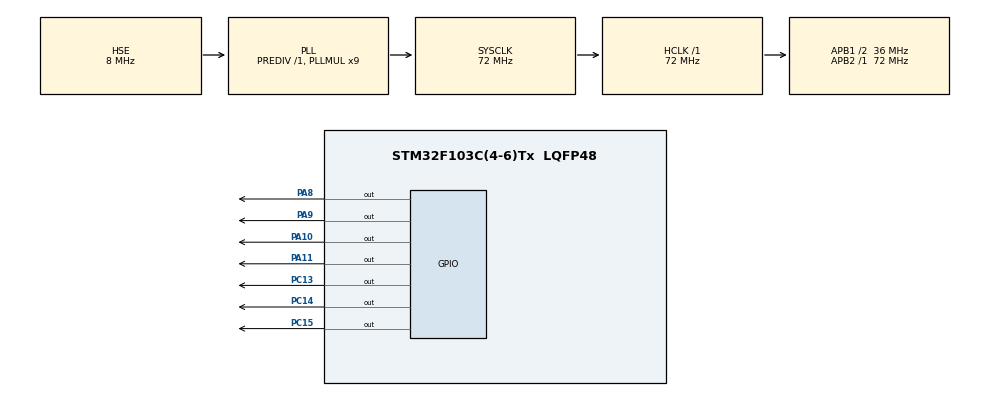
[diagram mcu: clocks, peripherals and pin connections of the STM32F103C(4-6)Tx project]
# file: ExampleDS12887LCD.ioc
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Mcu.Family=STM32F1
Mcu.Name=STM32F103C(4-6)Tx
Mcu.Package=LQFP48
NVIC.PriorityGroup=NVIC_PRIORITYGROUP_4
PA10.GPIO_ModeDefaultOutputPP=GPIO_MODE_OUTPUT_PP
PA10.GPIO_Speed=GPIO_SPEED_FREQ_HIGH
PA10.PinState=GPIO_PIN_RESET
PA10.Signal=GPIO_Output
PA11.GPIO_ModeDefaultOutputPP=GPIO_MODE_OUTPUT_PP
PA11.GPIO_Speed=GPIO_SPEED_FREQ_HIGH
PA11.PinState=GPIO_PIN_RESET
PA11.Signal=GPIO_Output
PA8.GPIO_ModeDefaultOutputPP=GPIO_MODE_OUTPUT_PP
PA8.GPIO_Speed=GPIO_SPEED_FREQ_HIGH
PA8.PinState=GPIO_PIN_RESET
PA8.Signal=GPIO_Output
PA9.GPIO_ModeDefaultOutputPP=GPIO_MODE_OUTPUT_PP
PA9.GPIO_Speed=GPIO_SPEED_FREQ_HIGH
PA9.PinState=GPIO_PIN_RESET
PA9.Signal=GPIO_Output
PC13-TAMPER-RTC.GPIO_ModeDefaultOutputPP=GPIO_MODE_OUTPUT_PP
PC13-TAMPER-RTC.GPIO_Speed=GPIO_SPEED_FREQ_HIGH
PC13-TAMPER-RTC.PinState=GPIO_PIN_RESET
PC13-TAMPER-RTC.Signal=GPIO_Output
PC14-OSC32_IN.GPIO_ModeDefaultOutputPP=GPIO_MODE_OUTPUT_PP
PC14-OSC32_IN.GPIO_Speed=GPIO_SPEED_FREQ_HIGH
PC14-OSC32_IN.PinState=GPIO_PIN_RESET
PC14-OSC32_IN.Signal=GPIO_Output
PC15-OSC32_OUT.GPIO_ModeDefaultOutputPP=GPIO_MODE_OUTPUT_PP
PC15-OSC32_OUT.GPIO_Speed=GPIO_SPEED_FREQ_HIGH
PC15-OSC32_OUT.PinState=GPIO_PIN_RESET
PC15-OSC32_OUT.Signal=GPIO_Output
PD0-OSC_IN.Mode=HSE-External-Oscillator
PD0-OSC_IN.Signal=RCC_OSC_IN
PD1-OSC_OUT.Mode=HSE-External-Oscillator
PD1-OSC_OUT.Signal=RCC_OSC_OUT
ProjectManager.HeapSize=0x200
ProjectManager.StackSize=0x400
ProjectManager.TargetToolchain=MDK-ARM V5
RCC.AHBFreq_Value=72000000
RCC.APB1CLKDivider=RCC_HCLK_DIV2
RCC.APB1Freq_Value=36000000
RCC.APB1TimFreq_Value=72000000
RCC.APB2Freq_Value=72000000
RCC.APB2TimFreq_Value=72000000
RCC.HCLKFreq_Value=72000000
RCC.PLLMUL=RCC_PLL_MUL9
RCC.PLLSourceVirtual=RCC_PLLSOURCE_HSE
RCC.SYSCLKFreq_VALUE=72000000
RCC.SYSCLKSource=RCC_SYSCLKSOURCE_PLLCLK
RCC.USBFreq_Value=72000000
VP_SYS_VS_ND.Mode=No_Debug
board=ExampleDS12887LCD

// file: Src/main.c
/**
  ******************************************************************************
  * @file           : main.c
  * @brief          : Main program body
  ******************************************************************************
  ** This notice applies to any and all portions of this file
  * that are not between comment pairs USER CODE BEGIN and
  * USER CODE END. Other portions of this file, whether
  * inserted by the user or by software development tools
  * are owned by their respective copyright owners.
  *
  * COPYRIGHT(c) 2018 STMicroelectronics
  *
  * Redistribution and use in source and binary forms, with or without modification,
  * are permitted provided that the following conditions are met:
  *   1. Redistributions of source code must retain the above copyright notice,
  *      this list of conditions and the following disclaimer.
  *   2. Redistributions in binary form must reproduce the above copyright notice,
  *      this list of conditions and the following disclaimer in the documentation
  *      and/or other materials provided with the distribution.
  *   3. Neither the name of STMicroelectronics nor the names of its contributors
  *      may be used to endorse or promote products derived from this software
  *      without specific prior written permission.
  *
  * THIS SOFTWARE IS PROVIDED BY THE COPYRIGHT HOLDERS AND CONTRIBUTORS "AS IS"
  * AND ANY EXPRESS OR IMPLIED WARRANTIES, INCLUDING, BUT NOT LIMITED TO, THE
  * IMPLIED WARRANTIES OF MERCHANTABILITY AND FITNESS FOR A PARTICULAR PURPOSE ARE
  * DISCLAIMED. IN NO EVENT SHALL THE COPYRIGHT HOLDER OR CONTRIBUTORS BE LIABLE
  * FOR ANY DIRECT, INDIRECT, INCIDENTAL, SPECIAL, EXEMPLARY, OR CONSEQUENTIAL
  * DAMAGES (INCLUDING, BUT NOT LIMITED TO, PROCUREMENT OF SUBSTITUTE GOODS OR
  * SERVICES; LOSS OF USE, DATA, OR PROFITS; OR BUSINESS INTERRUPTION) HOWEVER
  * CAUSED AND ON ANY THEORY OF LIABILITY, WHETHER IN CONTRACT, STRICT LIABILITY,
  * OR TORT (INCLUDING NEGLIGENCE OR OTHERWISE) ARISING IN ANY WAY OUT OF THE USE
  * OF THIS SOFTWARE, EVEN IF ADVISED OF THE POSSIBILITY OF SUCH DAMAGE.
  *
  ******************************************************************************
  */
#include "main.h"
#include "stm32f1xx_hal.h"
#include "lcd_txt.h"
#include "DS12887.h"

/* USER CODE BEGIN PV */
/* Private variables ---------------------------------------------------------*/
uint8_t second=0 ,minute=0,hour=16 ,day=1,date=1,month=1,year=20;
char str[32];

/* USER CODE END PV */

void SystemClock_Config(void);
static void MX_GPIO_Init(void);

/* USER CODE BEGIN PFP */
/* Private function prototypes -----------------------------------------------*/

/* USER CODE END PFP */

int main(void)
{

  /* MCU Configuration----------------------------------------------------------*/

  /* Reset of all peripherals, Initializes the Flash interface and the Systick. */
  HAL_Init();

  /* Configure the system clock */
  SystemClock_Config();

  /* Initialize all configured peripherals */
  MX_GPIO_Init();
	lcd_init();
	configpin_GPIO();
	DS12C887_Init();
	DS12C887_SetTime(hour,minute,second);
  DS12C887_SetDate(day,date,month,year);
//lcd_puts(0,0, (int8_t*) "hoang de nho");
  /* Infinite loop */
  /* USER CODE BEGIN WHILE */
  while (1)
  {
		DS12C887_GetTime(&hour,&minute,&second);
		DS12C887_GetDate(&day,&date,&month,&year);
		sprintf(str,"TIME: %2u:%2u:%2u",(uint16_t)hour,(uint16_t)minute,(uint16_t)second);
		lcd_puts(0, 0, str);
		sprintf(str,"DATE :%2u:%2u:%2u",(uint16_t)date,(uint16_t)month,(uint16_t)year);
		lcd_puts(1, 0, str);
		HAL_Delay(100);

  /* USER CODE END WHILE */

  }

}

void SystemClock_Config(void)
{

  RCC_OscInitTypeDef RCC_OscInitStruct;
  RCC_ClkInitTypeDef RCC_ClkInitStruct;

    /**Initializes the CPU, AHB and APB busses clocks
    */
  RCC_OscInitStruct.OscillatorType = RCC_OSCILLATORTYPE_HSE;
  RCC_OscInitStruct.HSEState = RCC_HSE_ON;
  RCC_OscInitStruct.HSEPredivValue = RCC_HSE_PREDIV_DIV1;
  RCC_OscInitStruct.HSIState = RCC_HSI_ON;
  RCC_OscInitStruct.PLL.PLLState = RCC_PLL_ON;
  RCC_OscInitStruct.PLL.PLLSource = RCC_PLLSOURCE_HSE;
  RCC_OscInitStruct.PLL.PLLMUL = RCC_PLL_MUL9;
  if (HAL_RCC_OscConfig(&RCC_OscInitStruct) != HAL_OK)
  {
    _Error_Handler(__FILE__, __LINE__);
  }

    /**Initializes the CPU, AHB and APB busses clocks
    */
  RCC_ClkInitStruct.ClockType = RCC_CLOCKTYPE_HCLK|RCC_CLOCKTYPE_SYSCLK
                              |RCC_CLOCKTYPE_PCLK1|RCC_CLOCKTYPE_PCLK2;
  RCC_ClkInitStruct.SYSCLKSource = RCC_SYSCLKSOURCE_PLLCLK;
  RCC_ClkInitStruct.AHBCLKDivider = RCC_SYSCLK_DIV1;
  RCC_ClkInitStruct.APB1CLKDivider = RCC_HCLK_DIV2;
  RCC_ClkInitStruct.APB2CLKDivider = RCC_HCLK_DIV1;

  if (HAL_RCC_ClockConfig(&RCC_ClkInitStruct, FLASH_LATENCY_2) != HAL_OK)
  {
    _Error_Handler(__FILE__, __LINE__);
  }

    /**Configure the Systick interrupt time
    */
  HAL_SYSTICK_Config(HAL_RCC_GetHCLKFreq()/1000);

    /**Configure the Systick
    */
  HAL_SYSTICK_CLKSourceConfig(SYSTICK_CLKSOURCE_HCLK);

  /* SysTick_IRQn interrupt configuration */
  HAL_NVIC_SetPriority(SysTick_IRQn, 0, 0);
}

/** Configure pins as
        * Analog
        * Input
        * Output
        * EVENT_OUT
        * EXTI
*/
static void MX_GPIO_Init(void)
{

  GPIO_InitTypeDef GPIO_InitStruct;

  /* GPIO Ports Clock Enable */
  __HAL_RCC_GPIOC_CLK_ENABLE();
  __HAL_RCC_GPIOD_CLK_ENABLE();
	 //__HAL_RCC_GPIOB_CLK_ENABLE();
  __HAL_RCC_GPIOA_CLK_ENABLE();

  /*Configure GPIO pin Output Level */
  HAL_GPIO_WritePin(GPIOC, GPIO_PIN_13|GPIO_PIN_14|GPIO_PIN_15, GPIO_PIN_RESET);

  /*Configure GPIO pin Output Level */
  HAL_GPIO_WritePin(GPIOA, GPIO_PIN_8|GPIO_PIN_9|GPIO_PIN_10|GPIO_PIN_11, GPIO_PIN_RESET);

  /*Configure GPIO pins : PC13 PC14 PC15 */
  GPIO_InitStruct.Pin = GPIO_PIN_13|GPIO_PIN_14|GPIO_PIN_15;
  GPIO_InitStruct.Mode = GPIO_MODE_OUTPUT_PP;
  GPIO_InitStruct.Speed = GPIO_SPEED_FREQ_HIGH;
  HAL_GPIO_Init(GPIOC, &GPIO_InitStruct);

  /*Configure GPIO pins : PA8 PA9 PA10 PA11 */
  GPIO_InitStruct.Pin = GPIO_PIN_8|GPIO_PIN_9|GPIO_PIN_10|GPIO_PIN_11;
  GPIO_InitStruct.Mode = GPIO_MODE_OUTPUT_PP;
  GPIO_InitStruct.Speed = GPIO_SPEED_FREQ_HIGH;
  HAL_GPIO_Init(GPIOA, &GPIO_InitStruct);

}

void _Error_Handler(char *file, int line)
{
  while(1)
  {
  }
}

/************************ (C) COPYRIGHT STMicroelectronics *****END OF FILE****/
